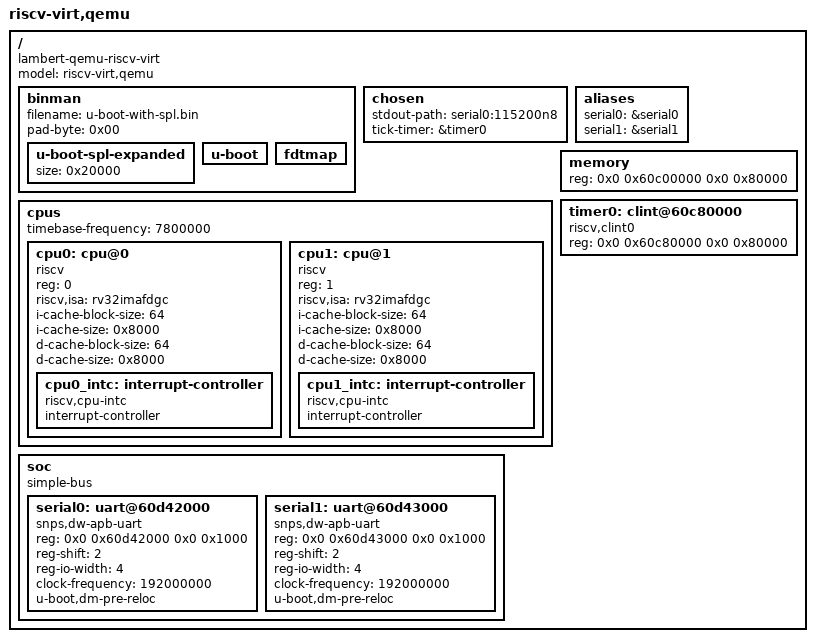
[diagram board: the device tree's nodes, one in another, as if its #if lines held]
// SPDX-License-Identifier: GPL-2.0+
/*
 * Copyright (C) 2023, Charleye <wangkart@aliyun.com>
 */


/dts-v1/;
#include <config.h>

/ {
	#address-cells = <2>;
	#size-cells = <2>;
	compatible = "lambert-qemu-riscv-virt";
	model = "riscv-virt,qemu";

	binman {
#ifdef CONFIG_LMT_RISCV_NO_DRAM
		filename = "u-boot-with-spl.bin";
		pad-byte = <0x00>;
		u-boot-spl-expanded {
			size = <0x20000>;
		};

		u-boot {
		};

		fdtmap {
		};
#endif
	};

	chosen {
		stdout-path = "serial0:115200n8";
		tick-timer = &timer0;
	};

	aliases {
		serial0 = &serial0;
		serial1 = &serial1;
	};

	cpus {
		#address-cells = <1>;
		#size-cells = <0>;
		timebase-frequency = <7800000>;
		cpu0: cpu@0 {
			device_type = "cpu";
			compatible = "riscv";
			reg = <0>;
			riscv,isa = "rv32imafdgc";
			i-cache-block-size = <64>;
			i-cache-size = <0x8000>;
			d-cache-block-size = <64>;
			d-cache-size = <0x8000>;
			cpu0_intc: interrupt-controller {
				#interrupt-cells = <1>;
				interrupt-controller;
				compatible = "riscv,cpu-intc";
			};
		};

		cpu1: cpu@1 {
			device_type = "cpu";
			compatible = "riscv";
			reg = <1>;
			riscv,isa = "rv32imafdgc";
			i-cache-block-size = <64>;
			i-cache-size = <0x8000>;
			d-cache-block-size = <64>;
			d-cache-size = <0x8000>;
			cpu1_intc: interrupt-controller {
				#interrupt-cells = <1>;
				interrupt-controller;
				compatible = "riscv,cpu-intc";
			};
		};
	};

	memory {
		device_type = "memory";
#ifdef CONFIG_LMT_RISCV_NO_DRAM
		reg = <0x0 0x60c00000 0x0 0x80000>;
#else
		reg = <0x0 0x60e00000 0x0 0x400000>;
#endif
	};

	timer0: clint@60c80000 {
		compatible = "riscv,clint0";
		reg = <0x0 0x60c80000 0x0 0x80000>;
	};

	soc {
		compatible = "simple-bus";
		#address-cells = <2>;
		#size-cells = <2>;
		ranges;

		serial0: uart@60d42000 {
			compatible = "snps,dw-apb-uart";
			reg = <0x0 0x60d42000 0x0 0x1000>;
			reg-shift = <2>;
			reg-io-width = <4>;
			// interrupts = <GIC_SPI 0x10 IRQ_TYPE_LEVEL_HIGH>;
			clock-frequency = <192000000>; //192MHz
			u-boot,dm-pre-reloc;
			u-boot,dm-spl;
			status = "okay";
		};

		serial1: uart@60d43000 {
			compatible = "snps,dw-apb-uart";
			reg = <0x0 0x60d43000 0x0 0x1000>;
			reg-shift = <2>;
			reg-io-width = <4>;
			// interrupts = <GIC_SPI 0x11 IRQ_TYPE_LEVEL_HIGH>;
			clock-frequency = <192000000>;
			u-boot,dm-pre-reloc;
			u-boot,dm-spl;
			status = "okay";
		};
	};
};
